VERSION "2.2.3.1-260706"

NS_ :

BS_:

BU_: Charger BMS Hub

BO_ 2566839038 SAE_SOFT: 8 Vector__XXX
 SG_ SWidentification : 8|8@1+ (1,0) [0|255] "" Vector__XXX

BO_ 2364607219 SAE_HVESSD8: 8 Vector__XXX
 SG_ AverageCellVoltage : 32|16@1+ (0.001,0) [0|65.535] "" Vector__XXX

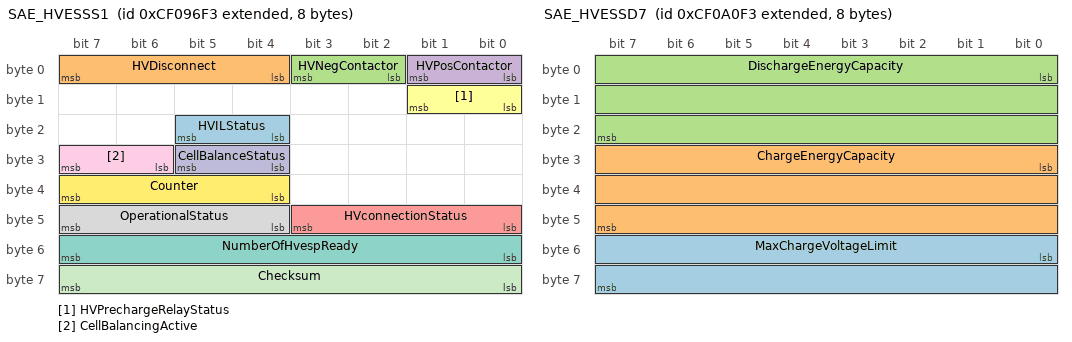
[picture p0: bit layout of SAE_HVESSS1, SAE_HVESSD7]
BO_ 2364577523 SAE_HVESSS1: 8 BMS
 SG_ HVILStatus : 20|2@1+ (1,0) [0|3] "" Vector__XXX
 SG_ HVDisconnect : 4|4@1+ (1,0) [0|15] "" Vector__XXX
 SG_ HVNegContactor : 2|2@1+ (1,0) [0|3] "" Vector__XXX
 SG_ HVPosContactor : 0|2@1+ (1,0) [0|3] "" Vector__XXX
 SG_ HVconnectionStatus : 40|4@1+ (1,0) [0|15] "" Vector__XXX
 SG_ HVPrechargeRelayStatus : 8|2@1+ (1,0) [0|3] "" Vector__XXX
 SG_ NumberOfHvespReady : 48|8@1+ (1,0) [0|250] "" Vector__XXX
 SG_ OperationalStatus : 44|4@1+ (1,0) [0|15] "" Vector__XXX
 SG_ CellBalancingActive : 30|2@1+ (1,0) [0|3] "" Vector__XXX
 SG_ CellBalanceStatus : 28|2@1+ (1,0) [0|3] "" Vector__XXX
 SG_ Checksum : 56|8@1+ (1,0) [0|255] "" Vector__XXX
 SG_ Counter : 36|4@1+ (1,0) [0|15] "" Vector__XXX

BO_ 2633785075 SAE_HVESSHIST: 40 BMS
 SG_ ConOpnUdrLoadCount : 8|16@1+ (1,0) [0|65535] "" Vector__XXX
 SG_ RemainingChargeTime : 280|16@1+ (1,0) [0|64255] "min" Vector__XXX
 SG_ RemainingRunTime : 264|16@1+ (1,0) [0|64255] "min" Vector__XXX
 SG_ LifetimeMinCellVoltage : 256|8@1+ (0.02044,0) [0|5.11] "V" Vector__XXX
 SG_ LifetimeMaxCellVoltage : 248|8@1+ (0.02044,0) [0|5.11] "V" Vector__XXX
 SG_ LifetimeMinPackVoltage : 232|16@1+ (0.05,0) [0|3212.75] "V" Vector__XXX
 SG_ LifetimeMaxPackVoltage : 216|16@1+ (0.05,0) [0|3212.75] "V" Vector__XXX
 SG_ LifetimeMinCurrent : 200|16@1+ (0.05,-1600) [-1600|1612.75] "A" Vector__XXX
 SG_ LifetimeMaxCurrent : 184|16@1+ (0.05,-1600) [-1600|1612.75] "A" Vector__XXX
 SG_ LifetimeMinTemp : 168|16@1+ (0.03125,-273) [-273|1734.96875] "C" Vector__XXX
 SG_ LifetimeMaxTemp : 152|16@1+ (0.03125,-273) [-273|1734.96875] "C" Vector__XXX
 SG_ TotalLifetimeEnergyOutput : 120|32@1+ (1,0) [0|4211081215] "kWh" Vector__XXX
 SG_ TotalLifetimeEnergyInput : 88|32@1+ (1,0) [0|4211081215] "kWh" Vector__XXX
 SG_ TotalAccumulatedCharge : 56|32@1+ (100,0) [0|421108121500] "Ah" Vector__XXX
 SG_ TotalEnergyThroughput : 24|32@1+ (100,0) [0|421108121500] "Wh" Vector__XXX
 SG_ SoH : 0|8@1+ (0.4,0) [0|100] "%" Vector__XXX

BO_ 2566675955 SAE_HVESSCFG: 17 BMS
 SG_ NumberOfHvespConfigured : 128|8@1+ (1,0) [0|250] "" Vector__XXX
 SG_ CellMinVoltageLimit : 120|8@1+ (0.02044,0) [0|5.11] "V" Vector__XXX
 SG_ CellMaxVoltageLimit : 112|8@1+ (0.02044,0) [0|5.11] "V" Vector__XXX
 SG_ RecommendedMinOperatingTemp : 96|16@1+ (0.03125,-273) [-273|1734.96875] "C" Vector__XXX
 SG_ RecommendedMaxOperatingTemp : 80|16@1+ (0.03125,-273) [-273|1734.96875] "C" Vector__XXX
 SG_ RecommendedMaxSoc : 64|16@1+ (0.0015625,0) [0|100.3984375] "%" Vector__XXX
 SG_ RecommendedMinSoc : 48|16@1+ (0.0015625,0) [0|100.3984375] "%" Vector__XXX
 SG_ RecommendedMaxOperatingVoltage : 32|16@1+ (0.05,0) [0|3212.75] "V" Vector__XXX
 SG_ RecommendedMinOperatingVoltage : 16|16@1+ (0.05,0) [0|3212.75] "V" Vector__XXX
 SG_ NominalVoltage : 0|16@1+ (0.05,0) [0|3212.75] "V" Vector__XXX

BO_ 2364580083 SAE_HVESSD7: 8 BMS
 SG_ MaxChargeVoltageLimit : 48|16@1+ (0.05,0) [0|3212.75] "V" Vector__XXX
 SG_ ChargeEnergyCapacity : 24|24@1+ (0.001,0) [0|16449.535] "kWh" Vector__XXX
 SG_ DischargeEnergyCapacity : 0|24@1+ (0.001,0) [0|16449.535] "kWh" Vector__XXX

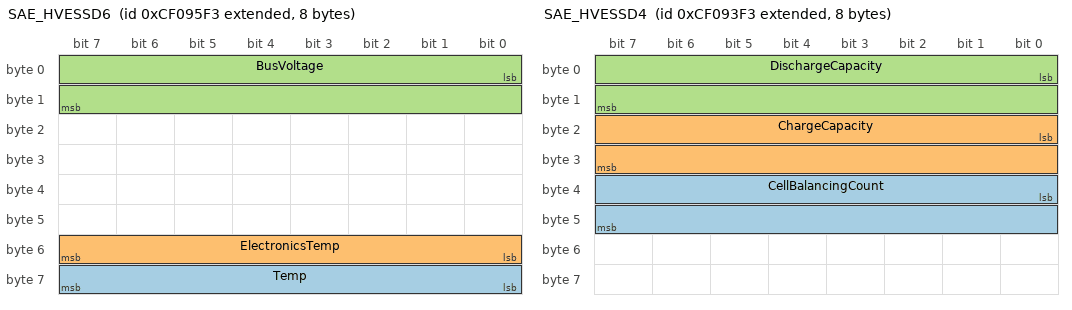
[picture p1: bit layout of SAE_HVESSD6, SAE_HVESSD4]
BO_ 2364577267 SAE_HVESSD6: 8 BMS
 SG_ Temp : 56|8@1+ (1,-40) [-40|210] "C" Vector__XXX
 SG_ ElectronicsTemp : 48|8@1+ (1,-40) [-40|210] "C" Vector__XXX
 SG_ BusVoltage : 0|16@1+ (0.05,0) [0|3212.75] "V" Vector__XXX

BO_ 2364577011 SAE_HVESSD5: 8 BMS
 SG_ ChargeCurrentLimit : 16|16@1+ (0.05,-1600) [-1600|1612.75] "A" Vector__XXX
 SG_ DischargeCurrentLimit : 0|16@1+ (0.05,-1600) [-1600|1612.75] "A" Vector__XXX

BO_ 2364576755 SAE_HVESSD4: 8 BMS
 SG_ CellBalancingCount : 32|16@1+ (1,0) [0|64255] "" Vector__XXX
 SG_ ChargeCapacity : 16|16@1+ (0.01,0) [0|642.55] "Ah" Vector__XXX
 SG_ DischargeCapacity : 0|16@1+ (0.01,0) [0|642.55] "Ah" Vector__XXX

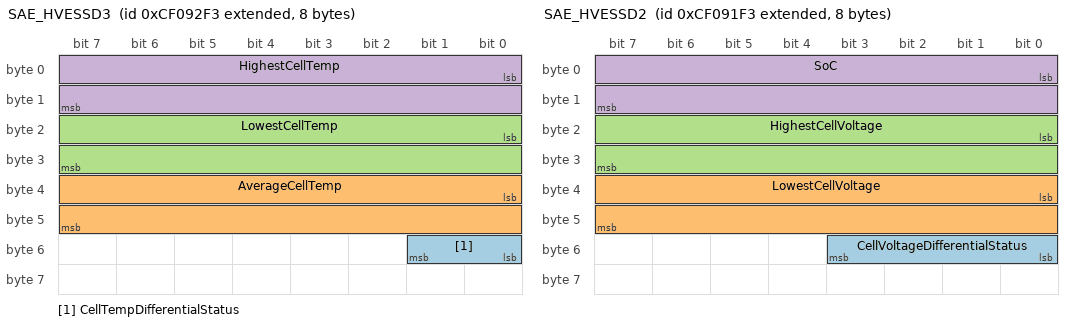
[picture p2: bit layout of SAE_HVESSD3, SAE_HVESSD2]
BO_ 2364576499 SAE_HVESSD3: 8 BMS
 SG_ CellTempDifferentialStatus : 48|2@1+ (1,0) [0|3] "" Vector__XXX
 SG_ AverageCellTemp : 32|16@1+ (0.03125,-273) [-273|1734.96875] "C" Vector__XXX
 SG_ LowestCellTemp : 16|16@1+ (0.03125,-273) [-273|1734.96875] "C" Vector__XXX
 SG_ HighestCellTemp : 0|16@1+ (0.03125,-273) [-273|1734.96875] "C" Vector__XXX

BO_ 2364576243 SAE_HVESSD2: 8 BMS
 SG_ CellVoltageDifferentialStatus : 48|4@1+ (1,0) [0|15] "" Vector__XXX
 SG_ LowestCellVoltage : 32|16@1+ (0.001,0) [0|64.255] "V" Vector__XXX
 SG_ HighestCellVoltage : 16|16@1+ (0.001,0) [0|64.255] "V" Vector__XXX
 SG_ SoC : 0|16@1+ (0.0015625,0) [0|100.3984375] "%" Vector__XXX

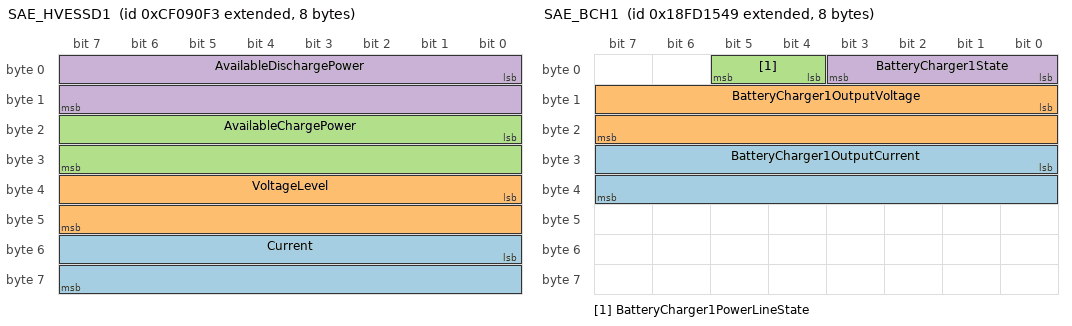
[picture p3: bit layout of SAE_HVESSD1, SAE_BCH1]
BO_ 2364575987 SAE_HVESSD1: 8 BMS
 SG_ Current : 48|16@1+ (0.05,-1600) [-1600|1612.75] "A" Vector__XXX
 SG_ VoltageLevel : 32|16@1+ (0.05,0) [0|3212.75] "V" Vector__XXX
 SG_ AvailableChargePower : 16|16@1+ (0.05,0) [0|3212.75] "kW" Vector__XXX
 SG_ AvailableDischargePower : 0|16@1+ (0.05,0) [0|3212.75] "kW" Vector__XXX

BO_ 2566722889 SAE_BCH1: 8 Charger
 SG_ BatteryCharger1OutputCurrent : 24|16@1+ (0.05,-1600) [-1600|1612.75] "A" Vector__XXX
 SG_ BatteryCharger1OutputVoltage : 8|16@1+ (0.05,0) [0|3212.75] "V" Vector__XXX
 SG_ BatteryCharger1PowerLineState : 4|2@1+ (1,0) [0|3] "" Vector__XXX
 SG_ BatteryCharger1State : 0|4@1+ (1,0) [0|15] "" Vector__XXX

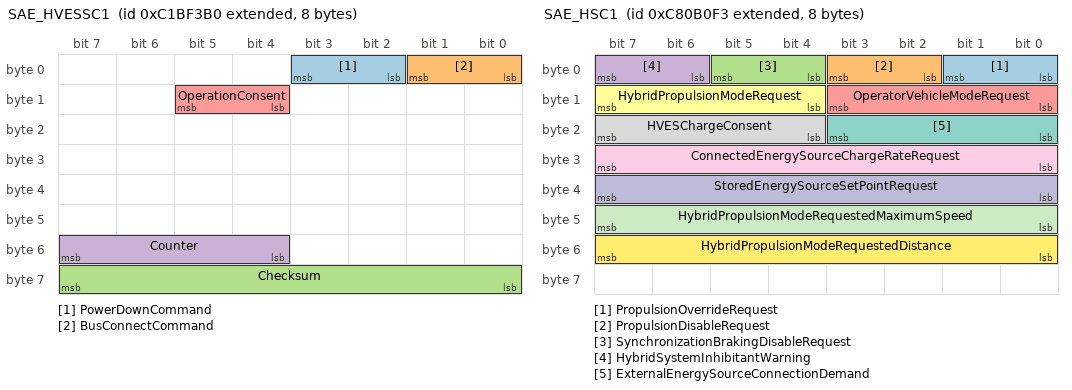
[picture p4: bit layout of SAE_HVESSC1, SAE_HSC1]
BO_ 2350642096 SAE_HVESSC1: 8 Hub
 SG_ PowerDownCommand : 2|2@1- (1,0) [0|0] "" Vector__XXX
 SG_ BusConnectCommand : 0|2@1+ (1,0) [0|3] "" Vector__XXX
 SG_ Checksum : 56|8@1+ (1,0) [0|255] "" Vector__XXX
 SG_ Counter : 52|4@1+ (1,0) [0|15] "" Vector__XXX
 SG_ OperationConsent : 12|2@1+ (1,0) [0|3] "" Vector__XXX

BO_ 2357244147 SAE_HSC1: 8 BMS
 SG_ PropulsionOverrideRequest : 0|2@1+ (1,0) [0|3] "" Hub
 SG_ PropulsionDisableRequest : 2|2@1+ (1,0) [0|3] "" Hub
 SG_ SynchronizationBrakingDisableRequest : 4|2@1+ (1,0) [0|3] "" Hub
 SG_ HybridSystemInhibitantWarning : 6|2@1+ (1,0) [0|3] "" Hub
 SG_ OperatorVehicleModeRequest : 8|4@1+ (1,0) [0|15] "" Hub
 SG_ HybridPropulsionModeRequest : 12|4@1+ (1,0) [0|15] "" Hub
 SG_ ExternalEnergySourceConnectionDemand : 16|4@1+ (1,0) [0|15] "" Hub
 SG_ HVESChargeConsent : 20|4@1+ (1,0) [0|15] "" Hub
 SG_ ConnectedEnergySourceChargeRateRequest : 24|8@1+ (1,0) [0|255] "" Hub
 SG_ StoredEnergySourceSetPointRequest : 32|8@1+ (1,0) [0|255] "" Hub
 SG_ HybridPropulsionModeRequestedMaximumSpeed : 40|8@1+ (1,0) [0|255] "km/h" Hub
 SG_ HybridPropulsionModeRequestedDistance : 48|8@1+ (1,0) [0|255] "km" Hub

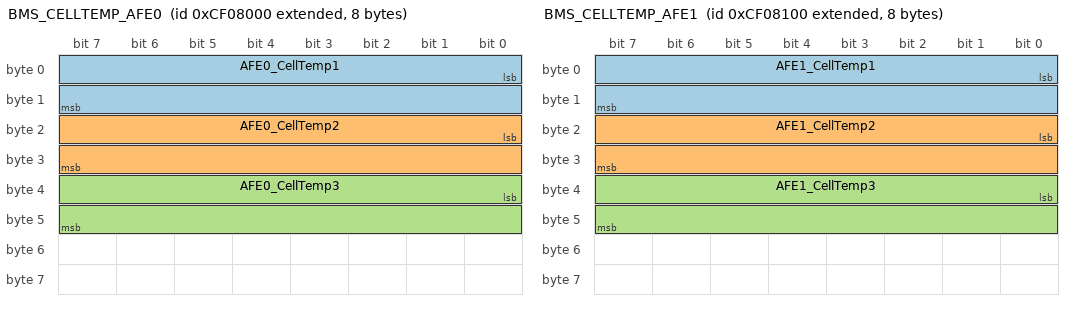
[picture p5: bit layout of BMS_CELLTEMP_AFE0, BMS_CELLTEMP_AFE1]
BO_ 2364571648 BMS_CELLTEMP_AFE0: 8 BMS
 SG_ AFE0_CellTemp1 : 0|16@1+ (0.1,-40) [-40|125] "C" Vector__XXX
 SG_ AFE0_CellTemp2 : 16|16@1+ (0.1,-40) [-40|125] "C" Vector__XXX
 SG_ AFE0_CellTemp3 : 32|16@1+ (0.1,-40) [-40|125] "C" Vector__XXX

BO_ 2364571904 BMS_CELLTEMP_AFE1: 8 BMS
 SG_ AFE1_CellTemp1 : 0|16@1+ (0.1,-40) [-40|125] "C" Vector__XXX
 SG_ AFE1_CellTemp2 : 16|16@1+ (0.1,-40) [-40|125] "C" Vector__XXX
 SG_ AFE1_CellTemp3 : 32|16@1+ (0.1,-40) [-40|125] "C" Vector__XXX

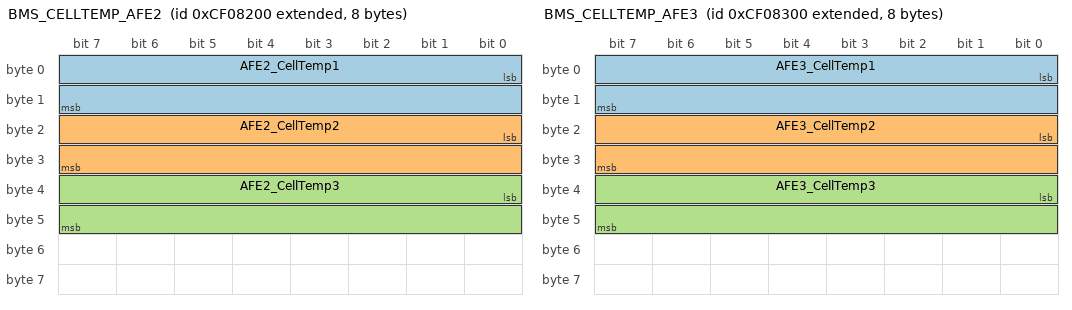
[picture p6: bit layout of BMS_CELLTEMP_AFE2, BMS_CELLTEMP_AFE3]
BO_ 2364572160 BMS_CELLTEMP_AFE2: 8 BMS
 SG_ AFE2_CellTemp1 : 0|16@1+ (0.1,-40) [-40|125] "C" Vector__XXX
 SG_ AFE2_CellTemp2 : 16|16@1+ (0.1,-40) [-40|125] "C" Vector__XXX
 SG_ AFE2_CellTemp3 : 32|16@1+ (0.1,-40) [-40|125] "C" Vector__XXX

BO_ 2364572416 BMS_CELLTEMP_AFE3: 8 BMS
 SG_ AFE3_CellTemp1 : 0|16@1+ (0.1,-40) [-40|125] "C" Vector__XXX
 SG_ AFE3_CellTemp2 : 16|16@1+ (0.1,-40) [-40|125] "C" Vector__XXX
 SG_ AFE3_CellTemp3 : 32|16@1+ (0.1,-40) [-40|125] "C" Vector__XXX

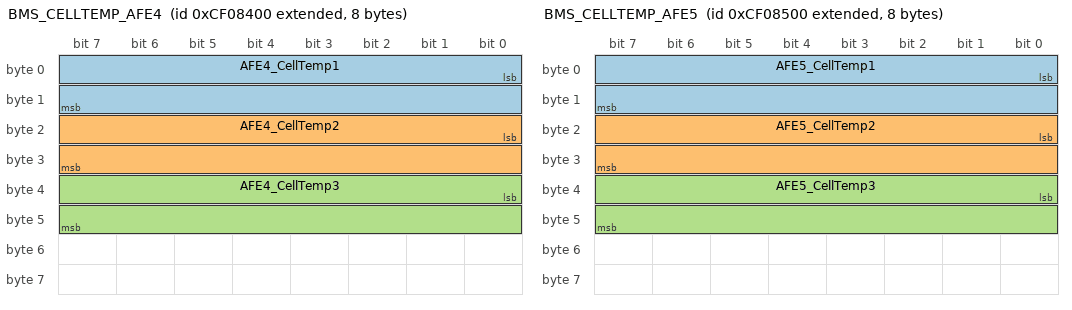
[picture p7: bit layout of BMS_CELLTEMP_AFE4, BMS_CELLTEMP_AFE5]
BO_ 2364572672 BMS_CELLTEMP_AFE4: 8 BMS
 SG_ AFE4_CellTemp1 : 0|16@1+ (0.1,-40) [-40|125] "C" Vector__XXX
 SG_ AFE4_CellTemp2 : 16|16@1+ (0.1,-40) [-40|125] "C" Vector__XXX
 SG_ AFE4_CellTemp3 : 32|16@1+ (0.1,-40) [-40|125] "C" Vector__XXX

BO_ 2364572928 BMS_CELLTEMP_AFE5: 8 BMS
 SG_ AFE5_CellTemp1 : 0|16@1+ (0.1,-40) [-40|125] "C" Vector__XXX
 SG_ AFE5_CellTemp2 : 16|16@1+ (0.1,-40) [-40|125] "C" Vector__XXX
 SG_ AFE5_CellTemp3 : 32|16@1+ (0.1,-40) [-40|125] "C" Vector__XXX

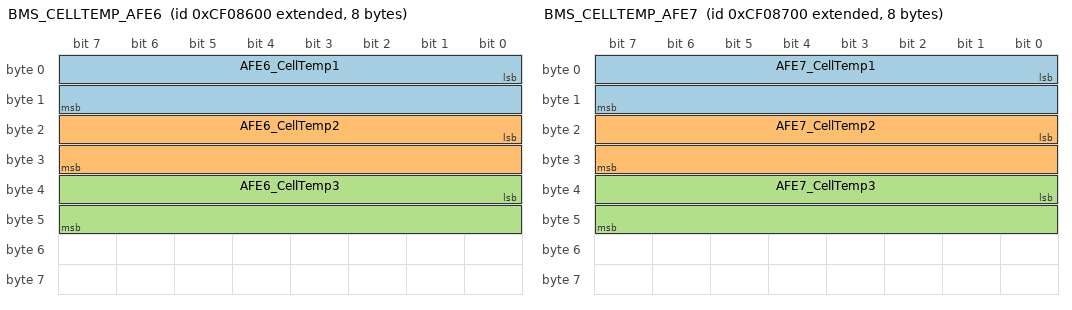
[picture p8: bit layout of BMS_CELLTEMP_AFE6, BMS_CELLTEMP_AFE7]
BO_ 2364573184 BMS_CELLTEMP_AFE6: 8 BMS
 SG_ AFE6_CellTemp1 : 0|16@1+ (0.1,-40) [-40|125] "C" Vector__XXX
 SG_ AFE6_CellTemp2 : 16|16@1+ (0.1,-40) [-40|125] "C" Vector__XXX
 SG_ AFE6_CellTemp3 : 32|16@1+ (0.1,-40) [-40|125] "C" Vector__XXX

BO_ 2364573440 BMS_CELLTEMP_AFE7: 8 BMS
 SG_ AFE7_CellTemp1 : 0|16@1+ (0.1,-40) [-40|125] "C" Vector__XXX
 SG_ AFE7_CellTemp2 : 16|16@1+ (0.1,-40) [-40|125] "C" Vector__XXX
 SG_ AFE7_CellTemp3 : 32|16@1+ (0.1,-40) [-40|125] "C" Vector__XXX

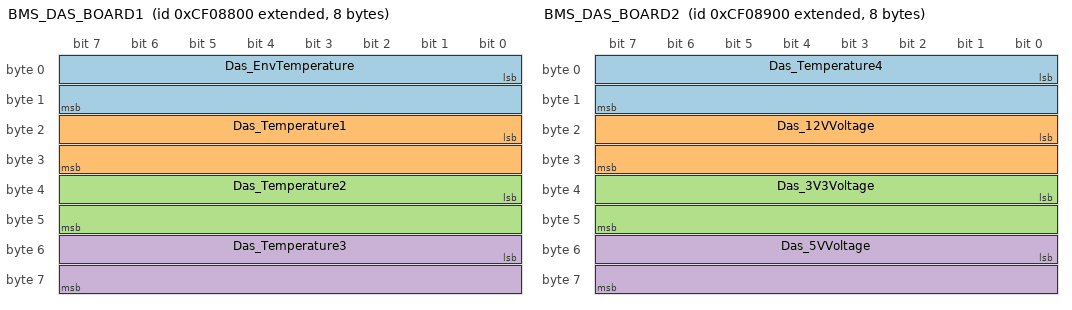
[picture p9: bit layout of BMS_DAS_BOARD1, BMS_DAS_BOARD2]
BO_ 2364573696 BMS_DAS_BOARD1: 8 BMS
 SG_ Das_EnvTemperature : 0|16@1+ (0.1,-40) [-40|125] "C" Vector__XXX
 SG_ Das_Temperature1 : 16|16@1+ (0.1,-40) [-40|125] "C" Vector__XXX
 SG_ Das_Temperature2 : 32|16@1+ (0.1,-40) [-40|125] "C" Vector__XXX
 SG_ Das_Temperature3 : 48|16@1+ (0.1,-40) [-40|125] "C" Vector__XXX

BO_ 2364573952 BMS_DAS_BOARD2: 8 BMS
 SG_ Das_Temperature4 : 0|16@1+ (0.1,-40) [-40|125] "C" Vector__XXX
 SG_ Das_12VVoltage : 16|16@1+ (0.001,0) [0|65.535] "V" Vector__XXX
 SG_ Das_3V3Voltage : 32|16@1+ (0.001,0) [0|65.535] "V" Vector__XXX
 SG_ Das_5VVoltage : 48|16@1+ (0.001,0) [0|65.535] "V" Vector__XXX

BO_ 2364574208 BMS_DAS_BOARD3: 8 BMS
 SG_ Das_HardwareVoltage : 0|16@1+ (0.001,0) [0|65.535] "V" Vector__XXX

BO_ 2364583936 BMS_BSUP_AFE0: 8 BMS
 SG_ AFE0_BsupVoltage : 0|16@1+ (0.01,0) [0|655.35] "V" Vector__XXX
 SG_ AFE0_BsupCurrent : 16|16@1+ (0.1,-5000) [-5000|1553.5] "A" Vector__XXX

BO_ 2364584192 BMS_BSUP_AFE1: 8 BMS
 SG_ AFE1_BsupVoltage : 0|16@1+ (0.01,0) [0|655.35] "V" Vector__XXX
 SG_ AFE1_BsupCurrent : 16|16@1+ (0.1,-5000) [-5000|1553.5] "A" Vector__XXX

BO_ 2364584448 BMS_BSUP_AFE2: 8 BMS
 SG_ AFE2_BsupVoltage : 0|16@1+ (0.01,0) [0|655.35] "V" Vector__XXX
 SG_ AFE2_BsupCurrent : 16|16@1+ (0.1,-5000) [-5000|1553.5] "A" Vector__XXX

BO_ 2364584704 BMS_BSUP_AFE3: 8 BMS
 SG_ AFE3_BsupVoltage : 0|16@1+ (0.01,0) [0|655.35] "V" Vector__XXX
 SG_ AFE3_BsupCurrent : 16|16@1+ (0.1,-5000) [-5000|1553.5] "A" Vector__XXX

BO_ 2364584960 BMS_BSUP_AFE4: 8 BMS
 SG_ AFE4_BsupVoltage : 0|16@1+ (0.01,0) [0|655.35] "V" Vector__XXX
 SG_ AFE4_BsupCurrent : 16|16@1+ (0.1,-5000) [-5000|1553.5] "A" Vector__XXX

BO_ 2364585216 BMS_BSUP_AFE5: 8 BMS
 SG_ AFE5_BsupVoltage : 0|16@1+ (0.01,0) [0|655.35] "V" Vector__XXX
 SG_ AFE5_BsupCurrent : 16|16@1+ (0.1,-5000) [-5000|1553.5] "A" Vector__XXX

BO_ 2364585472 BMS_BSUP_AFE6: 8 BMS
 SG_ AFE6_BsupVoltage : 0|16@1+ (0.01,0) [0|655.35] "V" Vector__XXX
 SG_ AFE6_BsupCurrent : 16|16@1+ (0.1,-5000) [-5000|1553.5] "A" Vector__XXX

BO_ 2364585728 BMS_BSUP_AFE7: 8 BMS
 SG_ AFE7_BsupVoltage : 0|16@1+ (0.01,0) [0|655.35] "V" Vector__XXX
 SG_ AFE7_BsupCurrent : 16|16@1+ (0.1,-5000) [-5000|1553.5] "A" Vector__XXX

CM_ BO_ 2364577523 "Status data set 1 for High Voltage Energy Storage System (or Pack 1 in systems with only one pack).";
CM_ BO_ 2633785075 "Historical data for High Voltage Energy Storage System (or Pack 1 in systems with only one pack).";
CM_ BO_ 2566675955 "Configuration data for High Voltage Energy Storage System (or Pack 1 in systems with only one pack).
Note that configuration data should not dynamically change during vehicle operation.";
CM_ BO_ 2364580083 "Data set 7 (electrical) for High Voltage Energy Storage System (or Pack 1 in systems with only one pack).";
CM_ BO_ 2364577267 "Data set 6 (external or interface data) for High Voltage Energy Storage System (or Pack 1 in systems with only one pack).";
CM_ BO_ 2364577011 "Data set 5 (electrical data) for High Voltage Energy Storage System (or Pack 1 in systems with only one pack).";
CM_ BO_ 2364576755 "Data set 4 (electrical data) for High Voltage Energy Storage System (or Pack 1 in systems with only one pack).";
CM_ BO_ 2364576499 "Data set 3 (thermal data) for High Voltage Energy Storage System (or Pack 1 in systems with only one pack).";
CM_ BO_ 2364576243 "Data set 2 (electrical data) for High Voltage Energy Storage System (or Pack 1 in systems with only one pack).";
CM_ BO_ 2364575987 "Data set 1 (electrical data) for High Voltage Energy Storage System (or Pack 1 in systems with only one pack).";
CM_ BO_ 2566722889 "Parameters for the battery charger connected to the main battery.";
CM_ BO_ 2350642096 "Control commands to be sent to High Voltage Energy Storage System (or Pack 1 in systems with only one pack).";
CM_ BO_ 2357244147 "Hybrid System Configuration 1 (PGN 32768 / 0x8000). Transmitted from BMS (SA 0xF3) to Hub (DA 0xB0). Transmission rate: Every 1 s and on change but no faster than 100 ms.";
CM_ BO_ 2364571648 "TempTest AFE0 cell temperatures. CAN ID 0x0CF08000. Unit 0.1C offset +40C. Invalid=0xFFFF.";
CM_ BO_ 2364571904 "TempTest AFE1 cell temperatures. CAN ID 0x0CF08100. Unit 0.1C offset +40C. Invalid=0xFFFF.";
CM_ BO_ 2364572160 "TempTest AFE2 cell temperatures. CAN ID 0x0CF08200. Unit 0.1C offset +40C. Invalid=0xFFFF.";
CM_ BO_ 2364572416 "TempTest AFE3 cell temperatures. CAN ID 0x0CF08300. Unit 0.1C offset +40C. Invalid=0xFFFF.";
CM_ BO_ 2364572672 "TempTest AFE4 cell temperatures. CAN ID 0x0CF08400. Unit 0.1C offset +40C. Invalid=0xFFFF.";
CM_ BO_ 2364572928 "TempTest AFE5 cell temperatures. CAN ID 0x0CF08500. Unit 0.1C offset +40C. Invalid=0xFFFF.";
CM_ BO_ 2364573184 "TempTest AFE6 cell temperatures. CAN ID 0x0CF08600. Unit 0.1C offset +40C. Invalid=0xFFFF.";
CM_ BO_ 2364573440 "TempTest AFE7 cell temperatures. CAN ID 0x0CF08700. Unit 0.1C offset +40C. Invalid=0xFFFF.";
CM_ BO_ 2364573696 "TempTest DAS board 1. CAN ID 0x0CF08800. EnvTemp and Das_Temperature[0..2]. Unit 0.1C offset +40C.";
CM_ BO_ 2364573952 "TempTest DAS board 2. CAN ID 0x0CF08900. Das_Temperature[3], 12V/3V3/5V. Temp 0.1C offset +40C, voltage mV.";
CM_ BO_ 2364574208 "TempTest DAS board 3. CAN ID 0x0CF08A00. HardwareVoltage in mV.";
CM_ BO_ 2364583936 "TempTest AFE0 BSUP voltage/current. CAN ID 0x0CF0B000. Volt 0.01V, Current 0.1A offset -5000A.";
CM_ BO_ 2364584192 "TempTest AFE1 BSUP voltage/current. CAN ID 0x0CF0B100. Volt 0.01V, Current 0.1A offset -5000A.";
CM_ BO_ 2364584448 "TempTest AFE2 BSUP voltage/current. CAN ID 0x0CF0B200. Volt 0.01V, Current 0.1A offset -5000A.";
CM_ BO_ 2364584704 "TempTest AFE3 BSUP voltage/current. CAN ID 0x0CF0B300. Volt 0.01V, Current 0.1A offset -5000A.";
CM_ BO_ 2364584960 "TempTest AFE4 BSUP voltage/current. CAN ID 0x0CF0B400. Volt 0.01V, Current 0.1A offset -5000A.";
CM_ BO_ 2364585216 "TempTest AFE5 BSUP voltage/current. CAN ID 0x0CF0B500. Volt 0.01V, Current 0.1A offset -5000A.";
CM_ BO_ 2364585472 "TempTest AFE6 BSUP voltage/current. CAN ID 0x0CF0B600. Volt 0.01V, Current 0.1A offset -5000A.";
CM_ BO_ 2364585728 "TempTest AFE7 BSUP voltage/current. CAN ID 0x0CF0B700. Volt 0.01V, Current 0.1A offset -5000A.";
BA_DEF_ SG_  "SigType" ENUM  "Default","Range","RangeSigned","ASCII","Discrete","Control","ReferencePGN","DTC","StringDelimiter","StringLength","StringLengthControl","MessageCounter","MessageChecksum";
BA_DEF_ SG_  "GenSigEVName" STRING ;
BA_DEF_ SG_  "GenSigILSupport" ENUM  "No","Yes";
BA_DEF_ SG_  "GenSigSendType" ENUM  "Cyclic","OnWrite","OnWriteWithRepetition","OnChange","OnChangeWithRepetition","IfActive","IfActiveWithRepetition","NoSigSendType";
BA_DEF_ BO_  "GenMsgCycleTimeFast" INT 0 3600000;
BA_DEF_ SG_  "GenSigStartValue" INT 0 2147483647;
BA_DEF_ BO_  "GenMsgILSupport" ENUM  "No","Yes";
BA_DEF_ BU_  "NmStationAddress" INT 0 255;
BA_DEF_ BO_  "GenMsgSendType" ENUM  "cyclic","NotUsed","IfActive","NotUsed","NotUsed","NotUsed","NotUsed","NotUsed","noMsgSendType";
BA_DEF_ BO_  "GenMsgRequestable" INT 0 1;
BA_DEF_ BO_  "GenMsgCycleTime" INT 0 3600000;
BA_DEF_ SG_  "SPN" INT 0 524287;
BA_DEF_  "DBName" STRING ;
BA_DEF_  "BusType" STRING ;
BA_DEF_  "ProtocolType" STRING ;
BA_DEF_ BO_  "VFrameFormat" ENUM  "StandardCAN","ExtendedCAN","reserved","J1939PG";
BA_DEF_DEF_  "SigType" "Default";
BA_DEF_DEF_  "GenSigEVName" "Env@Nodename_@Signame";
BA_DEF_DEF_  "GenSigILSupport" "Yes";
BA_DEF_DEF_  "GenSigSendType" "NoSigSendType";
BA_DEF_DEF_  "GenMsgCycleTimeFast" 0;
BA_DEF_DEF_  "GenSigStartValue" 0;
BA_DEF_DEF_  "GenMsgILSupport" "Yes";
BA_DEF_DEF_  "NmStationAddress" 254;
BA_DEF_DEF_  "GenMsgSendType" "noMsgSendType";
BA_DEF_DEF_  "GenMsgRequestable" 1;
BA_DEF_DEF_  "GenMsgCycleTime" 0;
BA_DEF_DEF_  "SPN" 0;
BA_DEF_DEF_  "DBName" "";
BA_DEF_DEF_  "BusType" "CAN";
BA_DEF_DEF_  "ProtocolType" "J1939";
BA_DEF_DEF_  "VFrameFormat" "J1939PG";
BA_ "DBName" "ClassA_EBS_BMS_J1939_r02";
BA_ "NmStationAddress" BU_ Charger 73;
BA_ "NmStationAddress" BU_ BMS 243;
BA_ "NmStationAddress" BU_ Hub 176;
BA_ "GenMsgCycleTime" BO_ 2364577523 100;
BA_ "GenMsgCycleTime" BO_ 2364580083 100;
BA_ "GenMsgCycleTime" BO_ 2364577267 100;
BA_ "GenMsgCycleTime" BO_ 2364577011 20;
BA_ "GenMsgCycleTime" BO_ 2364576755 100;
BA_ "GenMsgCycleTime" BO_ 2364576499 20;
BA_ "GenMsgCycleTime" BO_ 2364576243 20;
BA_ "GenMsgCycleTime" BO_ 2364575987 20;
BA_ "GenMsgCycleTime" BO_ 2566722889 1000;
BA_ "GenMsgCycleTime" BO_ 2350642096 20;
BA_ "GenMsgCycleTime" BO_ 2357244147 1000;
BA_ "GenMsgCycleTimeFast" BO_ 2357244147 100;
BA_ "GenMsgCycleTime" BO_ 2364571648 100;
BA_ "GenMsgCycleTime" BO_ 2364571904 100;
BA_ "GenMsgCycleTime" BO_ 2364572160 100;
BA_ "GenMsgCycleTime" BO_ 2364572416 100;
BA_ "GenMsgCycleTime" BO_ 2364572672 100;
BA_ "GenMsgCycleTime" BO_ 2364572928 100;
BA_ "GenMsgCycleTime" BO_ 2364573184 100;
BA_ "GenMsgCycleTime" BO_ 2364573440 100;
BA_ "GenMsgCycleTime" BO_ 2364573696 100;
BA_ "GenMsgCycleTime" BO_ 2364573952 100;
BA_ "GenMsgCycleTime" BO_ 2364574208 100;
BA_ "GenMsgCycleTime" BO_ 2364583936 100;
BA_ "GenMsgCycleTime" BO_ 2364584192 100;
BA_ "GenMsgCycleTime" BO_ 2364584448 100;
BA_ "GenMsgCycleTime" BO_ 2364584704 100;
BA_ "GenMsgCycleTime" BO_ 2364584960 100;
BA_ "GenMsgCycleTime" BO_ 2364585216 100;
BA_ "GenMsgCycleTime" BO_ 2364585472 100;
BA_ "GenMsgCycleTime" BO_ 2364585728 100;
BA_ "SPN" SG_ 2364577523 NumberOfHvespReady 12905;
BA_ "SPN" SG_ 2364577523 OperationalStatus 8414;
BA_ "SPN" SG_ 2364577523 CellBalancingActive 8102;
BA_ "SPN" SG_ 2364577523 CellBalanceStatus 8101;
BA_ "SPN" SG_ 2364577523 Checksum 13014;
BA_ "SPN" SG_ 2364577523 Counter 13013;
BA_ "GenSigStartValue" SG_ 2633785075 LifetimeMinCurrent 32000;
BA_ "GenSigStartValue" SG_ 2633785075 LifetimeMaxCurrent 32000;
BA_ "GenSigStartValue" SG_ 2633785075 LifetimeMinTemp 8736;
BA_ "GenSigStartValue" SG_ 2633785075 LifetimeMaxTemp 8736;
BA_ "SPN" SG_ 2633785075 TotalLifetimeEnergyOutput 13366;
BA_ "SPN" SG_ 2633785075 TotalLifetimeEnergyInput 13365;
BA_ "SPN" SG_ 2633785075 TotalAccumulatedCharge 8212;
BA_ "SPN" SG_ 2633785075 TotalEnergyThroughput 8211;
BA_ "SPN" SG_ 2633785075 SoH 8121;
BA_ "SPN" SG_ 2566675955 NumberOfHvespConfigured 12904;
BA_ "SPN" SG_ 2566675955 CellMinVoltageLimit 8210;
BA_ "SPN" SG_ 2566675955 CellMaxVoltageLimit 8209;
BA_ "GenSigStartValue" SG_ 2566675955 RecommendedMinOperatingTemp 8736;
BA_ "SPN" SG_ 2566675955 RecommendedMinOperatingTemp 8208;
BA_ "GenSigStartValue" SG_ 2566675955 RecommendedMaxOperatingTemp 8736;
BA_ "SPN" SG_ 2566675955 RecommendedMaxOperatingTemp 8120;
BA_ "SPN" SG_ 2566675955 RecommendedMaxSoc 8119;
BA_ "SPN" SG_ 2566675955 RecommendedMinSoc 8118;
BA_ "SPN" SG_ 2566675955 RecommendedMaxOperatingVoltage 8117;
BA_ "SPN" SG_ 2566675955 RecommendedMinOperatingVoltage 8116;
BA_ "SPN" SG_ 2566675955 NominalVoltage 8115;
BA_ "SPN" SG_ 2364580083 MaxChargeVoltageLimit 8090;
BA_ "SPN" SG_ 2364580083 ChargeEnergyCapacity 8206;
BA_ "SPN" SG_ 2364580083 DischargeEnergyCapacity 8205;
BA_ "GenSigStartValue" SG_ 2364577267 Temp 40;
BA_ "SPN" SG_ 2364577267 Temp 9119;
BA_ "GenSigStartValue" SG_ 2364577267 ElectronicsTemp 40;
BA_ "SPN" SG_ 2364577267 ElectronicsTemp 8204;
BA_ "SPN" SG_ 2364577267 BusVoltage 8086;
BA_ "GenSigStartValue" SG_ 2364577011 ChargeCurrentLimit 32000;
BA_ "SPN" SG_ 2364577011 ChargeCurrentLimit 8083;
BA_ "GenSigStartValue" SG_ 2364577011 DischargeCurrentLimit 32000;
BA_ "SPN" SG_ 2364577011 DischargeCurrentLimit 8082;
BA_ "SPN" SG_ 2364576755 CellBalancingCount 8081;
BA_ "SPN" SG_ 2364576755 ChargeCapacity 8080;
BA_ "SPN" SG_ 2364576755 DischargeCapacity 8079;
BA_ "SPN" SG_ 2364576499 CellTempDifferentialStatus 8078;
BA_ "GenSigStartValue" SG_ 2364576499 AverageCellTemp 8736;
BA_ "SPN" SG_ 2364576499 AverageCellTemp 8077;
BA_ "GenSigStartValue" SG_ 2364576499 LowestCellTemp 8736;
BA_ "SPN" SG_ 2364576499 LowestCellTemp 8076;
BA_ "GenSigStartValue" SG_ 2364576499 HighestCellTemp 8736;
BA_ "SPN" SG_ 2364576499 HighestCellTemp 8075;
BA_ "SPN" SG_ 2364576243 CellVoltageDifferentialStatus 5924;
BA_ "SPN" SG_ 2364576243 LowestCellVoltage 5923;
BA_ "SPN" SG_ 2364576243 HighestCellVoltage 5922;
BA_ "SPN" SG_ 2364576243 SoC 5921;
BA_ "GenSigStartValue" SG_ 2364575987 Current 32000;
BA_ "SPN" SG_ 2364575987 Current 5920;
BA_ "SPN" SG_ 2364575987 VoltageLevel 5919;
BA_ "SPN" SG_ 2364575987 AvailableChargePower 5918;
BA_ "SPN" SG_ 2364575987 AvailableDischargePower 5917;
BA_ "GenSigStartValue" SG_ 2566722889 BatteryCharger1OutputCurrent 32000;
BA_ "SPN" SG_ 2350642096 BusConnectCommand 8123;
BA_ "SPN" SG_ 2350642096 Checksum 13028;
BA_ "SPN" SG_ 2350642096 Counter 13027;
BA_ "SPN" SG_ 2350642096 OperationConsent 8412;
BA_ "SPN" SG_ 2357244147 PropulsionOverrideRequest 7557;
BA_ "SPN" SG_ 2357244147 PropulsionDisableRequest 7558;
BA_ "SPN" SG_ 2357244147 SynchronizationBrakingDisableRequest 7559;
BA_ "SPN" SG_ 2357244147 HybridSystemInhibitantWarning 7880;
BA_ "SPN" SG_ 2357244147 OperatorVehicleModeRequest 7888;
BA_ "SPN" SG_ 2357244147 HybridPropulsionModeRequest 7889;
BA_ "SPN" SG_ 2357244147 ExternalEnergySourceConnectionDemand 7808;
BA_ "SPN" SG_ 2357244147 HVESChargeConsent 10148;
BA_ "SPN" SG_ 2357244147 ConnectedEnergySourceChargeRateRequest 13154;
BA_ "SPN" SG_ 2357244147 StoredEnergySourceSetPointRequest 7892;
BA_ "SPN" SG_ 2357244147 HybridPropulsionModeRequestedMaximumSpeed 9706;
BA_ "SPN" SG_ 2357244147 HybridPropulsionModeRequestedDistance 9707;
BA_ "GenSigStartValue" SG_ 2357244147 HVESChargeConsent 15;
VAL_ 2364577523 HVconnectionStatus 4 "Disconnected" 3 "Disconnection in Process" 2 "Connection in Process" 1 "Connected" 0 "Disconnected" ;
VAL_ 2364577523 OperationalStatus 15 "Not Available" 14 "Error" 13 "Reserved" 12 "Heating - Discharge" 11 "Charging" 10 "Pre-Charge" 9 "Heating - Charge" 8 "Pre-Heat" 7 "Charge Initialization In Process" 6 "Disabled - Internal Command" 5 "Disabled - External Command" 4 "Emergency Power Down" 3 "Normal Power Down" 2 "Operational" 1 "Initialization Complete" 0 "Initialization In Process" ;
VAL_ 2364577523 CellBalancingActive 3 "Not Available" 2 "Error" 1 "Active" 0 "Not Active" ;
VAL_ 2364577523 CellBalanceStatus 3 "Not Available" 2 "Error" 1 "Cells Unbalanced" 0 "Cells Balanced" ;
VAL_ 2364576499 CellTempDifferentialStatus 3 "Not Available" 2 "Error" 1 "Unacceptable" 0 "Acceptable" ;
VAL_ 2364576243 CellVoltageDifferentialStatus 15 "Not Available" 14 "Error" 13 "Reserved" 12 "Reserved" 11 "Reserved" 10 "Reserved" 9 "Reserved" 8 "Reserved" 7 "Reserved" 6 "Reserved" 5 "Reserved" 4 "Unknown" 3 "Cannot Balance" 2 "Requires Maintenance Balancing" 1 "Requires Auto-Balancing" 0 "Acceptable" ;
VAL_ 2566722889 BatteryCharger1PowerLineState 3 "Not Available" 2 "Error" 1 "Connected" 0 "Disconnected" ;
VAL_ 2566722889 BatteryCharger1State 15 "Not Available" 14 "Charger Failure" 13 "Battery Failure" 12 "Reserved" 11 "Reserved" 10 "Reserved" 9 "Reserved" 8 "Reserved" 7 "Reserved" 6 "Reserved" 5 "Reserved" 4 "Reserved" 3 "Reserved" 2 "Stand-by" 1 "Charging" 0 "Idling" ;
VAL_ 2350642096 PowerDownCommand 3 "Don't care/Take no action" 2 "Execute emergency power-down" 1 "Execute normal power-down" 0 "Power-down not requested" ;
VAL_ 2350642096 BusConnectCommand 3 "Not Available" 2 "Error" 1 "Closed" 0 "Open" ;
VAL_ 2350642096 OperationConsent 3 "Not Available" 2 "Error" 1 "Consent Given" 0 "Consent Revoked" ;
VAL_ 2357244147 PropulsionOverrideRequest 3 "Not Available" 2 "Error" 1 "Override Requested" 0 "No Request" ;
VAL_ 2357244147 PropulsionDisableRequest 3 "Not Available" 2 "Error" 1 "Disable Requested" 0 "No Request" ;
VAL_ 2357244147 SynchronizationBrakingDisableRequest 3 "Not Available" 2 "Error" 1 "Disable Requested" 0 "No Request" ;
VAL_ 2357244147 HybridSystemInhibitantWarning 3 "Not Available" 2 "Error" 1 "Warning Active" 0 "No Warning" ;
VAL_ 2357244147 ExternalEnergySourceConnectionDemand 15 "Not Available" 14 "Error" 13 "Reserved" 12 "Reserved" 11 "Reserved" 10 "Reserved" 9 "Reserved" 8 "Reserved" 7 "Reserved" 6 "Reserved" 5 "Reserved" 4 "Reserved" 3 "Reserved" 2 "Reserved" 1 "Reserved" 0 "Reserved" ;
VAL_ 2357244147 HVESChargeConsent 15 "Not Available" 3 "Not Available - Battery has fault or other safety issues" 2 "SAE Reserved" 1 "Charging Allowed" 0 "Charging Not Allowed - Battery Fully Charged" ;
